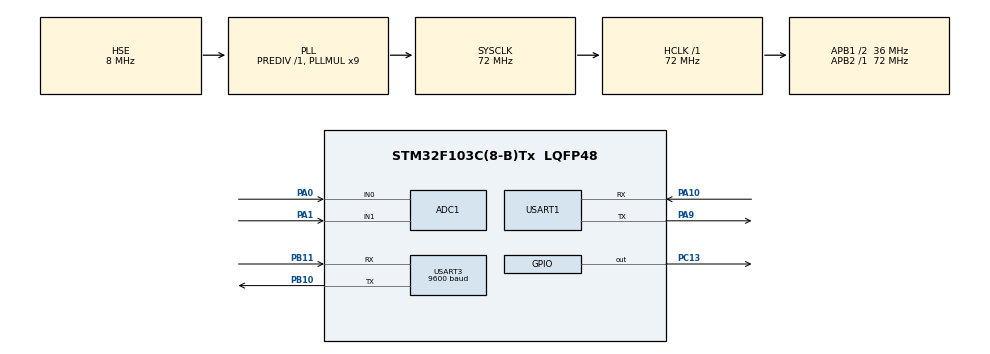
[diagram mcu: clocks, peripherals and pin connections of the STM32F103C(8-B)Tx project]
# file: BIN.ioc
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ADC1.Channel-0\#ChannelRegularConversion=ADC_CHANNEL_0
ADC1.Channel-1\#ChannelRegularConversion=ADC_CHANNEL_0
ADC1.ContinuousConvMode=ENABLE
ADC1.EnableInjectedConversion=DISABLE
ADC1.NbrOfConversion=2
ADC1.NbrOfConversionFlag=1
ADC1.Rank-0\#ChannelRegularConversion=1
ADC1.Rank-1\#ChannelRegularConversion=2
ADC1.SamplingTime-0\#ChannelRegularConversion=ADC_SAMPLETIME_1CYCLE_5
ADC1.SamplingTime-1\#ChannelRegularConversion=ADC_SAMPLETIME_1CYCLE_5
ADC1.master=1
Dma.Request0=USART3_RX
Dma.Request1=USART3_TX
Dma.USART3_RX.0.Direction=DMA_PERIPH_TO_MEMORY
Dma.USART3_RX.0.Instance=DMA1_Channel3
Dma.USART3_RX.0.MemDataAlignment=DMA_MDATAALIGN_BYTE
Dma.USART3_RX.0.MemInc=DMA_MINC_ENABLE
Dma.USART3_RX.0.Mode=DMA_NORMAL
Dma.USART3_RX.0.PeriphDataAlignment=DMA_PDATAALIGN_BYTE
Dma.USART3_RX.0.PeriphInc=DMA_PINC_DISABLE
Dma.USART3_RX.0.Priority=DMA_PRIORITY_LOW
Dma.USART3_TX.1.Direction=DMA_MEMORY_TO_PERIPH
Dma.USART3_TX.1.Instance=DMA1_Channel2
Dma.USART3_TX.1.MemDataAlignment=DMA_MDATAALIGN_BYTE
Dma.USART3_TX.1.MemInc=DMA_MINC_ENABLE
Dma.USART3_TX.1.Mode=DMA_NORMAL
Dma.USART3_TX.1.PeriphDataAlignment=DMA_PDATAALIGN_BYTE
Dma.USART3_TX.1.PeriphInc=DMA_PINC_DISABLE
Dma.USART3_TX.1.Priority=DMA_PRIORITY_LOW
Mcu.Family=STM32F1
Mcu.Name=STM32F103C(8-B)Tx
Mcu.Package=LQFP48
NVIC.ADC1_2_IRQn=true\:0\:0\:false\:false\:true\:true\:true
NVIC.DMA1_Channel2_IRQn=true\:0\:0\:false\:false\:true\:false\:true
NVIC.DMA1_Channel3_IRQn=true\:0\:0\:false\:false\:true\:false\:true
NVIC.PriorityGroup=NVIC_PRIORITYGROUP_4
NVIC.USART3_IRQn=true\:0\:0\:false\:false\:true\:true\:true
PA0-WKUP.Signal=ADCx_IN0
PA1.Signal=ADCx_IN1
PA10.Mode=Asynchronous
PA10.Signal=USART1_RX
PA13.Mode=Serial_Wire
PA13.Signal=SYS_JTMS-SWDIO
PA14.Mode=Serial_Wire
PA14.Signal=SYS_JTCK-SWCLK
PA9.Mode=Asynchronous
PA9.Signal=USART1_TX
PB10.Mode=Asynchronous
PB10.Signal=USART3_TX
PB11.Mode=Asynchronous
PB11.Signal=USART3_RX
PC13-TAMPER-RTC.Signal=GPIO_Output
PC14-OSC32_IN.Mode=LSE-External-Oscillator
PC14-OSC32_IN.Signal=RCC_OSC32_IN
PC15-OSC32_OUT.Mode=LSE-External-Oscillator
PC15-OSC32_OUT.Signal=RCC_OSC32_OUT
PD0-OSC_IN.Mode=HSE-External-Oscillator
PD0-OSC_IN.Signal=RCC_OSC_IN
PD1-OSC_OUT.Mode=HSE-External-Oscillator
PD1-OSC_OUT.Signal=RCC_OSC_OUT
ProjectManager.HeapSize=0x200
ProjectManager.StackSize=0x400
ProjectManager.TargetToolchain=MDK-ARM V5.27
RCC.ADCPresc=RCC_ADCPCLK2_DIV6
RCC.AHBFreq_Value=72000000
RCC.APB1CLKDivider=RCC_HCLK_DIV2
RCC.APB1Freq_Value=36000000
RCC.APB1TimFreq_Value=72000000
RCC.APB2Freq_Value=72000000
RCC.APB2TimFreq_Value=72000000
RCC.HCLKFreq_Value=72000000
RCC.PLLMUL=RCC_PLL_MUL9
RCC.PLLSourceVirtual=RCC_PLLSOURCE_HSE
RCC.SYSCLKFreq_VALUE=72000000
RCC.SYSCLKSource=RCC_SYSCLKSOURCE_PLLCLK
RCC.USBFreq_Value=72000000
SH.ADCx_IN0.0=ADC1_IN0,IN0
SH.ADCx_IN1.0=ADC1_IN1,IN1
USART1.VirtualMode=VM_ASYNC
USART3.BaudRate=9600
USART3.VirtualMode=VM_ASYNC
board=custom

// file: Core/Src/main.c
/* USER CODE BEGIN Header */
/**
  ******************************************************************************
  * @file           : main.c
  * @brief          : Main program body
  ******************************************************************************
  * @attention
  *
  * <h2><center>&copy; Copyright (c) 2024 STMicroelectronics.
  * All rights reserved.</center></h2>
  *
  * This software component is licensed by ST under BSD 3-Clause license,
  * the "License"; You may not use this file except in compliance with the
  * License. You may obtain a copy of the License at:
  *                        opensource.org/licenses/BSD-3-Clause
  *
  ******************************************************************************
  */
/* USER CODE END Header */
#include "main.h"
#include "adc.h"
#include "dma.h"
#include "usart.h"
#include "gpio.h"

/* USER CODE BEGIN Includes */
#include "stdio.h"
/* USER CODE END Includes */

void SystemClock_Config(void);

/* USER CODE BEGIN 0 */
uint16_t ADC_Value;
double Vol_Value;
uint16_t AD_Value;
uint32_t adc_values[2];
float x_position=0;
float y_position=0;
/* USER CODE END 0 */

int main(void)
{

  /* MCU Configuration--------------------------------------------------------*/

  /* Reset of all peripherals, Initializes the Flash interface and the Systick. */
  HAL_Init();

  /* Configure the system clock */
  SystemClock_Config();

  /* Initialize all configured peripherals */
  MX_GPIO_Init();
  MX_DMA_Init();
  MX_ADC1_Init();
  MX_USART1_UART_Init();
  MX_USART3_UART_Init();
  /* USER CODE BEGIN 2 */

	HAL_ADCEx_Calibration_Start(&hadc1);    //AD校准
	HAL_ADC_Start_DMA(&hadc1,adc_values,2);
  /* USER CODE BEGIN 2 */

  /* USER CODE END 2 */

  /* Infinite loop */
  while (1)
  {

  }
}

void SystemClock_Config(void)
{
  RCC_OscInitTypeDef RCC_OscInitStruct = {0};
  RCC_ClkInitTypeDef RCC_ClkInitStruct = {0};
  RCC_PeriphCLKInitTypeDef PeriphClkInit = {0};

  /** Initializes the RCC Oscillators according to the specified parameters
  * in the RCC_OscInitTypeDef structure.
  */
  RCC_OscInitStruct.OscillatorType = RCC_OSCILLATORTYPE_HSE;
  RCC_OscInitStruct.HSEState = RCC_HSE_ON;
  RCC_OscInitStruct.HSEPredivValue = RCC_HSE_PREDIV_DIV1;
  RCC_OscInitStruct.HSIState = RCC_HSI_ON;
  RCC_OscInitStruct.PLL.PLLState = RCC_PLL_ON;
  RCC_OscInitStruct.PLL.PLLSource = RCC_PLLSOURCE_HSE;
  RCC_OscInitStruct.PLL.PLLMUL = RCC_PLL_MUL9;
  if (HAL_RCC_OscConfig(&RCC_OscInitStruct) != HAL_OK)
  {
    Error_Handler();
  }
  /** Initializes the CPU, AHB and APB buses clocks
  */
  RCC_ClkInitStruct.ClockType = RCC_CLOCKTYPE_HCLK|RCC_CLOCKTYPE_SYSCLK
                              |RCC_CLOCKTYPE_PCLK1|RCC_CLOCKTYPE_PCLK2;
  RCC_ClkInitStruct.SYSCLKSource = RCC_SYSCLKSOURCE_PLLCLK;
  RCC_ClkInitStruct.AHBCLKDivider = RCC_SYSCLK_DIV1;
  RCC_ClkInitStruct.APB1CLKDivider = RCC_HCLK_DIV2;
  RCC_ClkInitStruct.APB2CLKDivider = RCC_HCLK_DIV1;

  if (HAL_RCC_ClockConfig(&RCC_ClkInitStruct, FLASH_LATENCY_2) != HAL_OK)
  {
    Error_Handler();
  }
  PeriphClkInit.PeriphClockSelection = RCC_PERIPHCLK_ADC;
  PeriphClkInit.AdcClockSelection = RCC_ADCPCLK2_DIV6;
  if (HAL_RCCEx_PeriphCLKConfig(&PeriphClkInit) != HAL_OK)
  {
    Error_Handler();
  }
}

/* USER CODE BEGIN 4 */
void HAL_ADC_ConvCpltCallback(ADC_HandleTypeDef* hadc)
{
    // 这里在 ADC 转换完成后处理数据
    // adc_values[0] 为 X 轴的 ADC 值
    // adc_values[1] 为 Y 轴的 ADC 值

    uint32_t x_value = adc_values[0];  // 获取 X 轴 ADC 值
    uint32_t y_value = adc_values[1];  // 获取 Y 轴 ADC 值

    // 将 ADC 值转换为电压值
    float x_voltage = (float)x_value * (3.3f / 4096.0f);  // X 轴电压值
    float y_voltage = (float)y_value * (3.3f / 4096.0f);  // Y 轴电压值

    // 在这里可以执行更多的数据处理逻辑，例如
    // 输出到串口、更新显示、触发事件等
}

/* USER CODE END 4 */

void Error_Handler(void)
{
}

/************************ (C) COPYRIGHT STMicroelectronics *****END OF FILE****/
